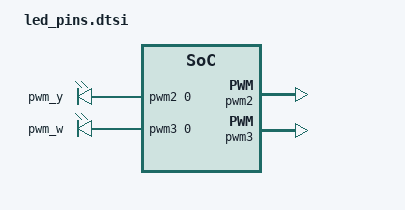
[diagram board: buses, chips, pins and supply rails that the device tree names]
/* Copyright 2022 The ChromiumOS Authors
 * Use of this source code is governed by a BSD-style license that can be
 * found in the LICENSE file.
 */

/ {
	pwmleds {
		compatible = "pwm-leds";
		pwm_y: pwm_y {
			pwms = <&pwm2 0 PWM_HZ(100) PWM_POLARITY_INVERTED>;
		};
		pwm_w: pwm_w {
			pwms = <&pwm3 0 PWM_HZ(100) PWM_POLARITY_INVERTED>;
		};
	};

	pwm-led-pins {
		compatible = "cros-ec,pwm-led-pins";

		color_off: color-off {
			led-color = "LED_OFF";
			led-id = "EC_LED_ID_BATTERY_LED";
			led-pwms = <&pwm_y &pwm_w>;
			led-values = <0 0>;
		};

		color_amber: color-amber {
			led-color = "LED_AMBER";
			led-id = "EC_LED_ID_BATTERY_LED";
			br-color = "EC_LED_COLOR_AMBER";
			led-pwms = <&pwm_y &pwm_w>;
			led-values = <100 0>;
		};

		color_white: color-white {
			led-color = "LED_WHITE";
			led-id = "EC_LED_ID_BATTERY_LED";
			br-color = "EC_LED_COLOR_WHITE";
			led-pwms = <&pwm_y &pwm_w>;
			led-values = <0 100>;
		};
	};
};

/* Amber "battery charging" LED */
&pwm2 {
	status = "okay";
	clock-bus = "NPCX_CLOCK_BUS_LFCLK";
	pinctrl-0 = <&pwm2_gpc4>;
	pinctrl-names = "default";
};

/* White "battery full" LED */
&pwm3 {
	status = "okay";
	clock-bus = "NPCX_CLOCK_BUS_LFCLK";
	pinctrl-0 = <&pwm3_gp80>;
	pinctrl-names = "default";
};
